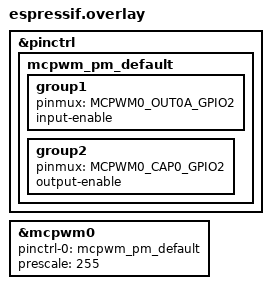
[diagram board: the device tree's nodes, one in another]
/*
 * Copyright (c) 2026 Espressif Systems (Shanghai) Co., Ltd.
 *
 * SPDX-License-Identifier: Apache-2.0
 */

/*
 * Output and capture share the pin, so capture measures that output.
 * The divider keeps a 10 ms period inside the timer.
 */
&pinctrl {
	mcpwm_pm_default: mcpwm_pm_default {
		group1 {
			pinmux = <MCPWM0_OUT0A_GPIO2>;
			input-enable;
		};

		group2 {
			pinmux = <MCPWM0_CAP0_GPIO2>;
			output-enable;
		};
	};
};

&mcpwm0 {
	pinctrl-0 = <&mcpwm_pm_default>;
	pinctrl-names = "default";
	prescale = <255>;
	status = "okay";
};
